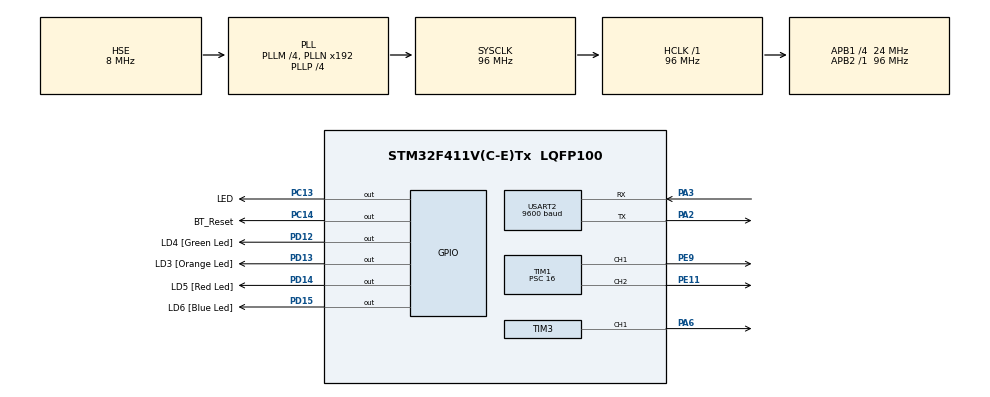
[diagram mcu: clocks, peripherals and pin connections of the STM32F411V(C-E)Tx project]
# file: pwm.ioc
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Mcu.Family=STM32F4
Mcu.Name=STM32F411V(C-E)Tx
Mcu.Package=LQFP100
NVIC.PriorityGroup=NVIC_PRIORITYGROUP_0
NVIC.TIM2_IRQn=true\:0\:0\:false\:false\:true\:true\:true
NVIC.TIM4_IRQn=true\:0\:0\:false\:false\:true\:true\:true
NVIC.USART2_IRQn=true\:0\:0\:false\:false\:true\:true\:true
PA13.GPIO_Label=SWDIO
PA13.Mode=Serial_Wire
PA13.Signal=SYS_JTMS-SWDIO
PA14.GPIO_Label=SWCLK
PA14.Mode=Serial_Wire
PA14.Signal=SYS_JTCK-SWCLK
PA2.Mode=Asynchronous
PA2.Signal=USART2_TX
PA3.Mode=Asynchronous
PA3.Signal=USART2_RX
PA6.Signal=S_TIM3_CH1
PC13-ANTI_TAMP.GPIO_Label=LED
PC13-ANTI_TAMP.PinState=GPIO_PIN_SET
PC13-ANTI_TAMP.Signal=GPIO_Output
PC14-OSC32_IN.GPIO_Label=BT_Reset
PC14-OSC32_IN.Signal=GPIO_Output
PC15-OSC32_OUT.GPIO_Label=PC15-OSC32_OUT
PC15-OSC32_OUT.Signal=RCC_OSC32_OUT
PD12.GPIO_Label=LD4 [Green Led]
PD12.GPIO_PuPd=GPIO_NOPULL
PD12.GPIO_Speed=GPIO_SPEED_FREQ_LOW
PD12.Signal=GPIO_Output
PD13.GPIO_Label=LD3 [Orange Led]
PD13.GPIO_PuPd=GPIO_NOPULL
PD13.GPIO_Speed=GPIO_SPEED_FREQ_LOW
PD13.Signal=GPIO_Output
PD14.GPIO_Label=LD5 [Red Led]
PD14.GPIO_PuPd=GPIO_NOPULL
PD14.GPIO_Speed=GPIO_SPEED_FREQ_LOW
PD14.Signal=GPIO_Output
PD15.GPIO_Label=LD6 [Blue Led]
PD15.GPIO_PuPd=GPIO_NOPULL
PD15.GPIO_Speed=GPIO_SPEED_FREQ_LOW
PD15.Signal=GPIO_Output
PE11.Signal=S_TIM1_CH2
PE9.Signal=S_TIM1_CH1
PH0\ -\ OSC_IN.Mode=HSE-External-Oscillator
PH0\ -\ OSC_IN.Signal=RCC_OSC_IN
PH1\ -\ OSC_OUT.Mode=HSE-External-Oscillator
PH1\ -\ OSC_OUT.Signal=RCC_OSC_OUT
ProjectManager.HeapSize=0x200
ProjectManager.StackSize=0x400
ProjectManager.TargetToolchain=STM32CubeIDE
RCC.48MHZClocksFreq_Value=48000000
RCC.AHBFreq_Value=96000000
RCC.APB1CLKDivider=RCC_HCLK_DIV4
RCC.APB1Freq_Value=24000000
RCC.APB1TimFreq_Value=48000000
RCC.APB2Freq_Value=96000000
RCC.APB2TimFreq_Value=96000000
RCC.CortexFreq_Value=96000000
RCC.HCLKFreq_Value=96000000
RCC.HSE_VALUE=8000000
RCC.HSI_VALUE=16000000
RCC.LSE_VALUE=32768
RCC.PLLI2SM=5
RCC.PLLI2SN=200
RCC.PLLM=4
RCC.PLLP=RCC_PLLP_DIV4
RCC.PLLQ=8
RCC.PLLSourceVirtual=RCC_PLLSOURCE_HSE
RCC.SYSCLKFreq_VALUE=96000000
RCC.SYSCLKSource=RCC_SYSCLKSOURCE_PLLCLK
RCC.VCOOutputFreq_Value=384000000
SH.S_TIM1_CH1.0=TIM1_CH1,PWM Generation1 CH1
SH.S_TIM1_CH2.0=TIM1_CH2,PWM Generation2 CH2
SH.S_TIM3_CH1.0=TIM3_CH1,PWM Generation1 CH1
TIM1.Channel-PWM\ Generation1\ CH1=TIM_CHANNEL_1
TIM1.Channel-PWM\ Generation2\ CH2=TIM_CHANNEL_2
TIM1.Period=100
TIM1.Prescaler=16
TIM1.Pulse-PWM\ Generation1\ CH1=80
TIM1.Pulse-PWM\ Generation2\ CH2=80
TIM2.Period=1999
TIM2.Prescaler=720
TIM3.Channel-PWM\ Generation1\ CH1=TIM_CHANNEL_1
TIM3.Period=20000
TIM3.Prescaler=48
TIM3.Pulse-PWM\ Generation1\ CH1=1000
TIM4.ClockDivision=TIM_CLOCKDIVISION_DIV1
TIM4.Period=1000
TIM4.Prescaler=32000
USART2.BaudRate=9600
USART2.VirtualMode=VM_ASYNC
VP_TIM1_VS_ClockSourceINT.Mode=Internal
VP_TIM2_VS_ClockSourceINT.Mode=Internal
VP_TIM3_VS_ClockSourceINT.Mode=Internal
VP_TIM4_VS_ClockSourceINT.Mode=Internal
board=STM32F411E-DISCO

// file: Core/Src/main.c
/* USER CODE BEGIN Header */
/**
  ******************************************************************************
  * @file           : main.c
  * @brief          : Main program body
  ******************************************************************************
  * @attention
  *
  * <h2><center>&copy; Copyright (c) 2020 STMicroelectronics.
  * All rights reserved.</center></h2>
  *
  * This software component is licensed by ST under Ultimate Liberty license
  * SLA0044, the "License"; You may not use this file except in compliance with
  * the License. You may obtain a copy of the License at:
  *                             www.st.com/SLA0044
  *
  ******************************************************************************
  */
/* USER CODE END Header */

#include "main.h"

/* USER CODE BEGIN Includes */
#include "bluetooth.h"
/* USER CODE END Includes */

TIM_HandleTypeDef htim1;
TIM_HandleTypeDef htim2;
TIM_HandleTypeDef htim3;
TIM_HandleTypeDef htim4;

UART_HandleTypeDef huart2;

void SystemClock_Config(void);
static void MX_GPIO_Init(void);
static void MX_USART2_UART_Init(void);
static void MX_TIM1_Init(void);
static void MX_TIM2_Init(void);
static void MX_TIM3_Init(void);
static void MX_TIM4_Init(void);

/* USER CODE BEGIN 0 */
int map(int st1, int fn1, int st2, int fn2, int value)
{
    return (1.0*(value-st1))/((fn1-st1)*1.0) * (fn2-st2)+st2;
}

void servo_write(int angle)
{
	htim3.Instance->CCR1 = map(0,180,50,250,angle);
}
/* USER CODE END 0 */

int main(void)
{

  /* MCU Configuration--------------------------------------------------------*/

  /* Reset of all peripherals, Initializes the Flash interface and the Systick. */
  HAL_Init();

  /* Configure the system clock */
  SystemClock_Config();

  /* Initialize all configured peripherals */
  MX_GPIO_Init();
  MX_USART2_UART_Init();
  MX_TIM1_Init();
  MX_TIM2_Init();
  MX_TIM3_Init();
  MX_TIM4_Init();
  /* USER CODE BEGIN 2 */
  HAL_Delay(1000);
  memset(buffer, 0, sizeof(buffer));
  HAL_TIM_Base_Start_IT(&htim2);
  __HAL_UART_ENABLE_IT(&huart2, UART_IT_RXNE);

  HAL_TIM_PWM_Start(&htim3, TIM_CHANNEL_1);
  HAL_Delay(250);
  /* USER CODE END 2 */

  /* Infinite loop */
  /* USER CODE BEGIN WHILE */
  while (1)
  {

	  //htim3.Instance->CCR1 = 1000;
	  //HAL_Delay(2000);
	  //htim3.Instance->CCR1 = 1000;
	  //HAL_Delay(2000);
	  //htim3.Instance->CCR1 = 2000;
	  //htim3.Instance->CCR1 = 1000;
	  //HAL_Delay(2000);
    /* USER CODE END WHILE */

  }
}

void SystemClock_Config(void)
{
  RCC_OscInitTypeDef RCC_OscInitStruct = {0};
  RCC_ClkInitTypeDef RCC_ClkInitStruct = {0};

  /** Configure the main internal regulator output voltage
  */
  __HAL_RCC_PWR_CLK_ENABLE();
  __HAL_PWR_VOLTAGESCALING_CONFIG(PWR_REGULATOR_VOLTAGE_SCALE1);
  /** Initializes the CPU, AHB and APB busses clocks
  */
  RCC_OscInitStruct.OscillatorType = RCC_OSCILLATORTYPE_HSE;
  RCC_OscInitStruct.HSEState = RCC_HSE_ON;
  RCC_OscInitStruct.PLL.PLLState = RCC_PLL_ON;
  RCC_OscInitStruct.PLL.PLLSource = RCC_PLLSOURCE_HSE;
  RCC_OscInitStruct.PLL.PLLM = 4;
  RCC_OscInitStruct.PLL.PLLN = 192;
  RCC_OscInitStruct.PLL.PLLP = RCC_PLLP_DIV4;
  RCC_OscInitStruct.PLL.PLLQ = 8;
  if (HAL_RCC_OscConfig(&RCC_OscInitStruct) != HAL_OK)
  {
    Error_Handler();
  }
  /** Initializes the CPU, AHB and APB busses clocks
  */
  RCC_ClkInitStruct.ClockType = RCC_CLOCKTYPE_HCLK|RCC_CLOCKTYPE_SYSCLK
                              |RCC_CLOCKTYPE_PCLK1|RCC_CLOCKTYPE_PCLK2;
  RCC_ClkInitStruct.SYSCLKSource = RCC_SYSCLKSOURCE_PLLCLK;
  RCC_ClkInitStruct.AHBCLKDivider = RCC_SYSCLK_DIV1;
  RCC_ClkInitStruct.APB1CLKDivider = RCC_HCLK_DIV4;
  RCC_ClkInitStruct.APB2CLKDivider = RCC_HCLK_DIV1;

  if (HAL_RCC_ClockConfig(&RCC_ClkInitStruct, FLASH_LATENCY_3) != HAL_OK)
  {
    Error_Handler();
  }
}

static void MX_TIM1_Init(void)
{

  TIM_ClockConfigTypeDef sClockSourceConfig = {0};
  TIM_MasterConfigTypeDef sMasterConfig = {0};
  TIM_OC_InitTypeDef sConfigOC = {0};
  TIM_BreakDeadTimeConfigTypeDef sBreakDeadTimeConfig = {0};

  htim1.Instance = TIM1;
  htim1.Init.Prescaler = 16;
  htim1.Init.CounterMode = TIM_COUNTERMODE_UP;
  htim1.Init.Period = 100;
  htim1.Init.ClockDivision = TIM_CLOCKDIVISION_DIV1;
  htim1.Init.RepetitionCounter = 0;
  htim1.Init.AutoReloadPreload = TIM_AUTORELOAD_PRELOAD_DISABLE;
  if (HAL_TIM_Base_Init(&htim1) != HAL_OK)
  {
    Error_Handler();
  }
  sClockSourceConfig.ClockSource = TIM_CLOCKSOURCE_INTERNAL;
  if (HAL_TIM_ConfigClockSource(&htim1, &sClockSourceConfig) != HAL_OK)
  {
    Error_Handler();
  }
  if (HAL_TIM_PWM_Init(&htim1) != HAL_OK)
  {
    Error_Handler();
  }
  sMasterConfig.MasterOutputTrigger = TIM_TRGO_RESET;
  sMasterConfig.MasterSlaveMode = TIM_MASTERSLAVEMODE_DISABLE;
  if (HAL_TIMEx_MasterConfigSynchronization(&htim1, &sMasterConfig) != HAL_OK)
  {
    Error_Handler();
  }
  sConfigOC.OCMode = TIM_OCMODE_PWM1;
  sConfigOC.Pulse = 80;
  sConfigOC.OCPolarity = TIM_OCPOLARITY_HIGH;
  sConfigOC.OCNPolarity = TIM_OCNPOLARITY_HIGH;
  sConfigOC.OCFastMode = TIM_OCFAST_DISABLE;
  sConfigOC.OCIdleState = TIM_OCIDLESTATE_RESET;
  sConfigOC.OCNIdleState = TIM_OCNIDLESTATE_RESET;
  if (HAL_TIM_PWM_ConfigChannel(&htim1, &sConfigOC, TIM_CHANNEL_1) != HAL_OK)
  {
    Error_Handler();
  }
  if (HAL_TIM_PWM_ConfigChannel(&htim1, &sConfigOC, TIM_CHANNEL_2) != HAL_OK)
  {
    Error_Handler();
  }
  sBreakDeadTimeConfig.OffStateRunMode = TIM_OSSR_DISABLE;
  sBreakDeadTimeConfig.OffStateIDLEMode = TIM_OSSI_DISABLE;
  sBreakDeadTimeConfig.LockLevel = TIM_LOCKLEVEL_OFF;
  sBreakDeadTimeConfig.DeadTime = 0;
  sBreakDeadTimeConfig.BreakState = TIM_BREAK_DISABLE;
  sBreakDeadTimeConfig.BreakPolarity = TIM_BREAKPOLARITY_HIGH;
  sBreakDeadTimeConfig.AutomaticOutput = TIM_AUTOMATICOUTPUT_DISABLE;
  if (HAL_TIMEx_ConfigBreakDeadTime(&htim1, &sBreakDeadTimeConfig) != HAL_OK)
  {
    Error_Handler();
  }
  HAL_TIM_MspPostInit(&htim1);

}

static void MX_TIM2_Init(void)
{

  TIM_ClockConfigTypeDef sClockSourceConfig = {0};
  TIM_MasterConfigTypeDef sMasterConfig = {0};

  htim2.Instance = TIM2;
  htim2.Init.Prescaler = 720;
  htim2.Init.CounterMode = TIM_COUNTERMODE_UP;
  htim2.Init.Period = 1999;
  htim2.Init.ClockDivision = TIM_CLOCKDIVISION_DIV1;
  htim2.Init.AutoReloadPreload = TIM_AUTORELOAD_PRELOAD_DISABLE;
  if (HAL_TIM_Base_Init(&htim2) != HAL_OK)
  {
    Error_Handler();
  }
  sClockSourceConfig.ClockSource = TIM_CLOCKSOURCE_INTERNAL;
  if (HAL_TIM_ConfigClockSource(&htim2, &sClockSourceConfig) != HAL_OK)
  {
    Error_Handler();
  }
  sMasterConfig.MasterOutputTrigger = TIM_TRGO_RESET;
  sMasterConfig.MasterSlaveMode = TIM_MASTERSLAVEMODE_DISABLE;
  if (HAL_TIMEx_MasterConfigSynchronization(&htim2, &sMasterConfig) != HAL_OK)
  {
    Error_Handler();
  }

}

static void MX_TIM3_Init(void)
{

  TIM_ClockConfigTypeDef sClockSourceConfig = {0};
  TIM_MasterConfigTypeDef sMasterConfig = {0};
  TIM_OC_InitTypeDef sConfigOC = {0};

  htim3.Instance = TIM3;
  htim3.Init.Prescaler = 48;
  htim3.Init.CounterMode = TIM_COUNTERMODE_UP;
  htim3.Init.Period = 20000;
  htim3.Init.ClockDivision = TIM_CLOCKDIVISION_DIV1;
  htim3.Init.AutoReloadPreload = TIM_AUTORELOAD_PRELOAD_DISABLE;
  if (HAL_TIM_Base_Init(&htim3) != HAL_OK)
  {
    Error_Handler();
  }
  sClockSourceConfig.ClockSource = TIM_CLOCKSOURCE_INTERNAL;
  if (HAL_TIM_ConfigClockSource(&htim3, &sClockSourceConfig) != HAL_OK)
  {
    Error_Handler();
  }
  if (HAL_TIM_PWM_Init(&htim3) != HAL_OK)
  {
    Error_Handler();
  }
  sMasterConfig.MasterOutputTrigger = TIM_TRGO_RESET;
  sMasterConfig.MasterSlaveMode = TIM_MASTERSLAVEMODE_DISABLE;
  if (HAL_TIMEx_MasterConfigSynchronization(&htim3, &sMasterConfig) != HAL_OK)
  {
    Error_Handler();
  }
  sConfigOC.OCMode = TIM_OCMODE_PWM1;
  sConfigOC.Pulse = 1000;
  sConfigOC.OCPolarity = TIM_OCPOLARITY_HIGH;
  sConfigOC.OCFastMode = TIM_OCFAST_DISABLE;
  if (HAL_TIM_PWM_ConfigChannel(&htim3, &sConfigOC, TIM_CHANNEL_1) != HAL_OK)
  {
    Error_Handler();
  }
  HAL_TIM_MspPostInit(&htim3);

}

static void MX_TIM4_Init(void)
{

  TIM_ClockConfigTypeDef sClockSourceConfig = {0};
  TIM_MasterConfigTypeDef sMasterConfig = {0};

  htim4.Instance = TIM4;
  htim4.Init.Prescaler = 32000;
  htim4.Init.CounterMode = TIM_COUNTERMODE_UP;
  htim4.Init.Period = 1000;
  htim4.Init.ClockDivision = TIM_CLOCKDIVISION_DIV1;
  htim4.Init.AutoReloadPreload = TIM_AUTORELOAD_PRELOAD_DISABLE;
  if (HAL_TIM_Base_Init(&htim4) != HAL_OK)
  {
    Error_Handler();
  }
  sClockSourceConfig.ClockSource = TIM_CLOCKSOURCE_INTERNAL;
  if (HAL_TIM_ConfigClockSource(&htim4, &sClockSourceConfig) != HAL_OK)
  {
    Error_Handler();
  }
  sMasterConfig.MasterOutputTrigger = TIM_TRGO_RESET;
  sMasterConfig.MasterSlaveMode = TIM_MASTERSLAVEMODE_DISABLE;
  if (HAL_TIMEx_MasterConfigSynchronization(&htim4, &sMasterConfig) != HAL_OK)
  {
    Error_Handler();
  }

}

static void MX_USART2_UART_Init(void)
{

  huart2.Instance = USART2;
  huart2.Init.BaudRate = 9600;
  huart2.Init.WordLength = UART_WORDLENGTH_8B;
  huart2.Init.StopBits = UART_STOPBITS_1;
  huart2.Init.Parity = UART_PARITY_NONE;
  huart2.Init.Mode = UART_MODE_TX_RX;
  huart2.Init.HwFlowCtl = UART_HWCONTROL_NONE;
  huart2.Init.OverSampling = UART_OVERSAMPLING_16;
  if (HAL_UART_Init(&huart2) != HAL_OK)
  {
    Error_Handler();
  }

}

static void MX_GPIO_Init(void)
{
  GPIO_InitTypeDef GPIO_InitStruct = {0};

  /* GPIO Ports Clock Enable */
  __HAL_RCC_GPIOC_CLK_ENABLE();
  __HAL_RCC_GPIOH_CLK_ENABLE();
  __HAL_RCC_GPIOA_CLK_ENABLE();
  __HAL_RCC_GPIOE_CLK_ENABLE();
  __HAL_RCC_GPIOD_CLK_ENABLE();

  /*Configure GPIO pin Output Level */
  HAL_GPIO_WritePin(LED_GPIO_Port, LED_Pin, GPIO_PIN_SET);

  /*Configure GPIO pin Output Level */
  HAL_GPIO_WritePin(BT_Reset_GPIO_Port, BT_Reset_Pin, GPIO_PIN_RESET);

  /*Configure GPIO pin Output Level */
  HAL_GPIO_WritePin(GPIOD, LD4_Pin|LD3_Pin|LD5_Pin|LD6_Pin, GPIO_PIN_RESET);

  /*Configure GPIO pins : LED_Pin BT_Reset_Pin */
  GPIO_InitStruct.Pin = LED_Pin|BT_Reset_Pin;
  GPIO_InitStruct.Mode = GPIO_MODE_OUTPUT_PP;
  GPIO_InitStruct.Pull = GPIO_NOPULL;
  GPIO_InitStruct.Speed = GPIO_SPEED_FREQ_LOW;
  HAL_GPIO_Init(GPIOC, &GPIO_InitStruct);

  /*Configure GPIO pins : LD4_Pin LD3_Pin LD5_Pin LD6_Pin */
  GPIO_InitStruct.Pin = LD4_Pin|LD3_Pin|LD5_Pin|LD6_Pin;
  GPIO_InitStruct.Mode = GPIO_MODE_OUTPUT_PP;
  GPIO_InitStruct.Pull = GPIO_NOPULL;
  GPIO_InitStruct.Speed = GPIO_SPEED_FREQ_LOW;
  HAL_GPIO_Init(GPIOD, &GPIO_InitStruct);

}

void Error_Handler(void)
{
  /* USER CODE BEGIN Error_Handler_Debug */
  /* User can add his own implementation to report the HAL error return state */
	HAL_GPIO_WritePin(LD4_Pin, LED_Pin, SET);
  /* USER CODE END Error_Handler_Debug */
}

/************************ (C) COPYRIGHT STMicroelectronics *****END OF FILE****/
